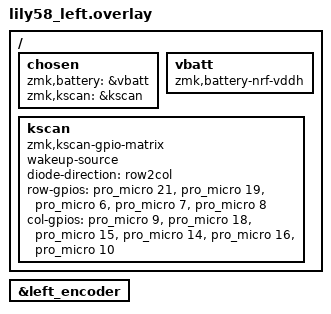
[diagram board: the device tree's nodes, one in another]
/*
 * Copyright (c) 2020 Pete Johanson
 *
 * SPDX-License-Identifier: MIT
 */

#include "lily58.dtsi"

// &kscan0 {
//     col-gpios
//         = <&pro_micro 19 GPIO_ACTIVE_HIGH>
//         , <&pro_micro 18 GPIO_ACTIVE_HIGH>
//         , <&pro_micro 15 GPIO_ACTIVE_HIGH>
//         , <&pro_micro 14 GPIO_ACTIVE_HIGH>
//         , <&pro_micro 16 GPIO_ACTIVE_HIGH>
//         , <&pro_micro 10 GPIO_ACTIVE_HIGH>
//         ;
// };

/ {
    chosen {
        zmk,battery = &vbatt;
        zmk,kscan = &kscan;
    };

    vbatt: vbatt {
        compatible = "zmk,battery-nrf-vddh";
    };

    kscan: kscan {
        compatible = "zmk,kscan-gpio-matrix";
        wakeup-source;

        diode-direction = "row2col";

        row-gpios
            = <&pro_micro 21 GPIO_ACTIVE_HIGH>
            , <&pro_micro 19 GPIO_ACTIVE_HIGH>
            , <&pro_micro 6  GPIO_ACTIVE_HIGH>
            , <&pro_micro 7  GPIO_ACTIVE_HIGH>
            , <&pro_micro 8  GPIO_ACTIVE_HIGH>
            ;

        col-gpios
            = <&pro_micro 9  (GPIO_PULL_DOWN | GPIO_ACTIVE_HIGH)>
            , <&pro_micro 18 (GPIO_PULL_DOWN | GPIO_ACTIVE_HIGH)>
            , <&pro_micro 15 (GPIO_PULL_DOWN | GPIO_ACTIVE_HIGH)>
            , <&pro_micro 14 (GPIO_PULL_DOWN | GPIO_ACTIVE_HIGH)>
            , <&pro_micro 16 (GPIO_PULL_DOWN | GPIO_ACTIVE_HIGH)>
            , <&pro_micro 10 (GPIO_PULL_DOWN | GPIO_ACTIVE_HIGH)>
            ;
    };
};

&left_encoder {
    status = "okay";
};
